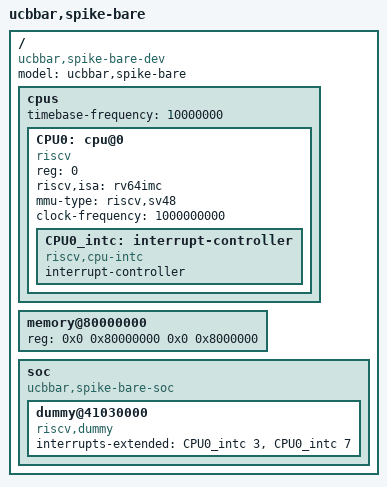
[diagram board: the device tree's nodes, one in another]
/dts-v1/;

/ {
  #address-cells = <2>;
  #size-cells = <2>;
  compatible = "ucbbar,spike-bare-dev";
  model = "ucbbar,spike-bare";
  cpus {
    #address-cells = <1>;
    #size-cells = <0>;
    timebase-frequency = <10000000>;
    CPU0: cpu@0 {
      device_type = "cpu";
      reg = <0>;
      status = "okay";
      compatible = "riscv";
      riscv,isa = "rv64imc";
      mmu-type = "riscv,sv48";
      clock-frequency = <1000000000>;
      CPU0_intc: interrupt-controller {
        #interrupt-cells = <1>;
        interrupt-controller;
        compatible = "riscv,cpu-intc";
      };
    };
  };
  memory@80000000 {
    device_type = "memory";
    reg = <0x0 0x80000000 0x0 0x8000000>;
  };
  soc {
    #address-cells = <2>;
    #size-cells = <2>;
    compatible = "ucbbar,spike-bare-soc", "simple-bus";
    ranges;
    dummy@41030000 {
      compatible = "riscv,dummy";
      interrupts-extended = <&CPU0_intc 3 &CPU0_intc 7 >;
    };
  };
};
